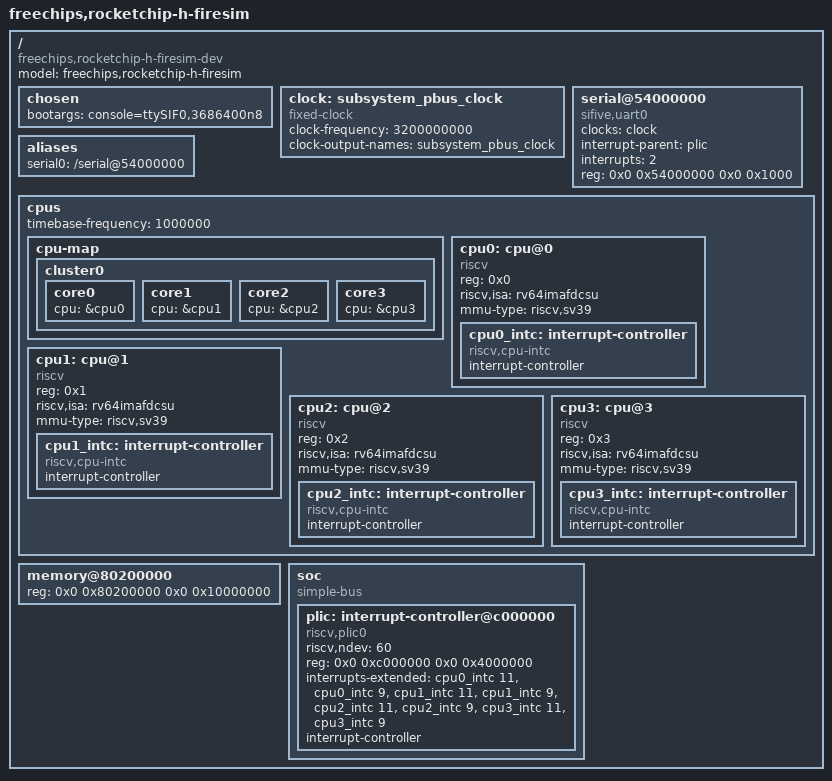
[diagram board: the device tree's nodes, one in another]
/dts-v1/;

/ {
	#address-cells = <0x2>;
	#size-cells = <0x2>;
	compatible = "freechips,rocketchip-h-firesim-dev";
	model = "freechips,rocketchip-h-firesim";

	chosen {
		bootargs = "console=ttySIF0,3686400n8";
	};	

	clock: subsystem_pbus_clock {
		#clock-cells = <0>;
		clock-frequency = <3200000000>;
		clock-output-names = "subsystem_pbus_clock";
		compatible = "fixed-clock";
	};

	serial@54000000 {
		clocks = <&clock>;
		compatible = "sifive,uart0";
		interrupt-parent = <&plic>;
		interrupts = <2>;
		reg = <0x0 0x54000000 0x0 0x1000>;
		reg-names = "control";
        status = "okay";
	};

    aliases {
        serial0 = "/serial@54000000";
    };

	cpus {
		#address-cells = <0x1>;
		#size-cells = <0x0>;
		timebase-frequency = <1000000>;

		cpu-map {

			cluster0 {

				core0 {
					cpu = &cpu0;
				};

				core1 {
					cpu = &cpu1;
				};

				core2 {
					cpu = &cpu2;
				};

				core3 {
					cpu = &cpu3;
				};
			};
		};

		cpu0: cpu@0 {
			device_type = "cpu";
			reg = <0x0>;
			status = "okay";
			compatible = "riscv";
			riscv,isa = "rv64imafdcsu";
			mmu-type = "riscv,sv39";

			cpu0_intc: interrupt-controller {
				#interrupt-cells = <0x1>;
				interrupt-controller;
				compatible = "riscv,cpu-intc";
			};
		};

		cpu1: cpu@1 {
			device_type = "cpu";
			reg = <0x1>;
			status = "okay";
			compatible = "riscv";
			riscv,isa = "rv64imafdcsu";
			mmu-type = "riscv,sv39";

			cpu1_intc: interrupt-controller {
				#interrupt-cells = <0x1>;
				interrupt-controller;
				compatible = "riscv,cpu-intc";
			};
		};

		cpu2: cpu@2 {
			device_type = "cpu";
			reg = <0x2>;
			status = "okay";
			compatible = "riscv";
			riscv,isa = "rv64imafdcsu";
			mmu-type = "riscv,sv39";

			cpu2_intc: interrupt-controller {
				#interrupt-cells = <0x1>;
				interrupt-controller;
				compatible = "riscv,cpu-intc";
			};
		};

		cpu3: cpu@3 {
			device_type = "cpu";
			reg = <0x3>;
			status = "okay";
			compatible = "riscv";
			riscv,isa = "rv64imafdcsu";
			mmu-type = "riscv,sv39";

			cpu3_intc: interrupt-controller {
				#interrupt-cells = <0x1>;
				interrupt-controller;
				compatible = "riscv,cpu-intc";
			};
		};
	};

	memory@80200000 {
		device_type = "memory";
		reg = <0x0 0x80200000 0x0 0x10000000>;
	};

	soc {
		#address-cells = <0x2>;
		#size-cells = <0x2>;
		compatible = "simple-bus";
		ranges;

		plic: interrupt-controller@c000000 {
			riscv,ndev = <60>;
			reg = <0x0 0xc000000 0x0 0x4000000>;
			interrupts-extended = <
            	&cpu0_intc 11 &cpu0_intc 9 
              	&cpu1_intc 11 &cpu1_intc 9 
              	&cpu2_intc 11 &cpu2_intc 9
				&cpu3_intc 11 &cpu3_intc 9
            >;
			interrupt-controller;
			compatible = "riscv,plic0";
			#interrupt-cells = <0x1>;
			#address-cells = <0x0>;
		};

	};
};
